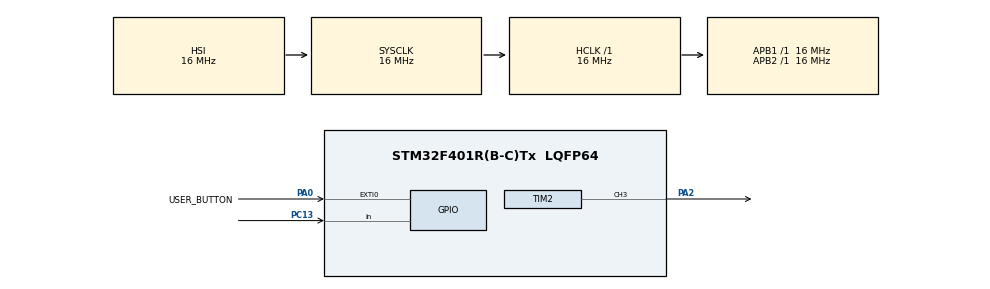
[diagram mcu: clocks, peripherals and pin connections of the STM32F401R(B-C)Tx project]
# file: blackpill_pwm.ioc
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Mcu.Family=STM32F4
Mcu.Name=STM32F401R(B-C)Tx
Mcu.Package=LQFP64
NVIC.EXTI0_IRQn=true\:0\:0\:false\:false\:true\:true\:true\:true
NVIC.PriorityGroup=NVIC_PRIORITYGROUP_4
PA0-WKUP.GPIO_Label=USER_BUTTON
PA0-WKUP.GPIO_ModeDefaultEXTI=GPIO_MODE_IT_FALLING
PA0-WKUP.GPIO_PuPd=GPIO_PULLUP
PA0-WKUP.Signal=GPXTI0
PA2.Signal=S_TIM2_CH3
PC13-ANTI_TAMP.Signal=GPIO_Input
ProjectManager.HeapSize=0x200
ProjectManager.StackSize=0x400
ProjectManager.TargetToolchain=STM32CubeIDE
RCC.AHBFreq_Value=16000000
RCC.APB1Freq_Value=16000000
RCC.APB2Freq_Value=16000000
RCC.CortexFreq_Value=16000000
RCC.HSE_VALUE=25000000
RCC.HSI_VALUE=16000000
RCC.LSE_VALUE=32768
RCC.SYSCLKFreq_VALUE=16000000
RCC.VCOOutputFreq_Value=192000000
SH.S_TIM2_CH3.0=TIM2_CH3,PWM Generation3 CH3
TIM2.Channel-PWM\ Generation3\ CH3=TIM_CHANNEL_3
TIM2.OCPolarity_3=TIM_OCPOLARITY_LOW
TIM2.Period=511
VP_TIM2_VS_ClockSourceINT.Mode=Internal
board=custom

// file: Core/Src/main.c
/* USER CODE BEGIN Header */
/**
  ******************************************************************************
  * @file           : main.c
  * @brief          : Main program body
  ******************************************************************************
  * @attention
  *
  * Copyright (c) 2025 STMicroelectronics.
  * All rights reserved.
  *
  * This software is licensed under terms that can be found in the LICENSE file
  * in the root directory of this software component.
  * If no LICENSE file comes with this software, it is provided AS-IS.
  *
  ******************************************************************************
  */
/* USER CODE END Header */
#include "main.h"

TIM_HandleTypeDef htim2;

void SystemClock_Config(void);
static void MX_GPIO_Init(void);
static void MX_TIM2_Init(void);

/* USER CODE BEGIN 0 */

uint8_t keyPress = 0; //A variable to keep track of no.of times the user button is pressed, set to 0 on startup
uint16_t pwmValue; //A variable to give as input to SET_COMPARE command

void HAL_GPIO_EXTI_Callback(uint16_t GPIO_Pin) //Called whenever user button is pressed
{
	keyPress++; //Increment the variable to denote that the button has been pressed
	if(keyPress>1) //Check if button is pressed has been pressed more than once
	{
		keyPress = 0; //If so reset it back to the "default" state
	}
}

/* USER CODE END 0 */

int main(void)
{

  /* MCU Configuration--------------------------------------------------------*/

  /* Reset of all peripherals, Initializes the Flash interface and the Systick. */
  HAL_Init();

  /* Configure the system clock */
  SystemClock_Config();

  /* Initialize all configured peripherals */
  MX_GPIO_Init();
  MX_TIM2_Init();

  /* Infinite loop */
  while (1)
  {

    /* USER CODE BEGIN 3 */

	  //PWM pin A2 is physically mapped to C13 for making user LED to glow using PWM
	  //Since C13 is an active low pin, PWM's CH polarity is set to low inside ioc file
	  //Otherwise LED will start at max brightness and decrease to min brightness which I don't want

	  if(keyPress) //Only execute if the button is pressed in odd number of times i.e 1st, 3rd, 5th etc as 0th, 2nd, 4th means PWM is OFF
	  {
		 HAL_TIM_PWM_Start(&htim2, TIM_CHANNEL_3); //Start PWM
		 __HAL_TIM_SET_COMPARE(&htim2, TIM_CHANNEL_3, pwmValue); //Set PWM's pulse value on the fly
		 HAL_Delay(3); //Give a short delay between each pulse value to make the brightness change visible
		 if(pwmValue>=512) //Max value of pulse should be less than 512 (counter period is set to 511 aka 9 bits)
		 {
			 pwmValue = 0; //Reset pulse value back to 0
		 }
		 else
		 {
			 pwmValue++; //Increase pulse value by 1
		 }
	  }
	  else //Only execute if the button is pressed in even number of times i.e 2nd, 4th, 6th etc as 1st, 3rd, 5th means PWM is ON
	  {
		  HAL_TIM_PWM_Stop(&htim2, TIM_CHANNEL_3); //Stop PWM to turn OFF the LED
		  pwmValue = 0; //Set pulse value to 0 so that when user presses button to turn PWM back ON, LED will start from min brightness and gradually increase
	  }
  }
  /* USER CODE END 3 */
}

void SystemClock_Config(void)
{
  RCC_OscInitTypeDef RCC_OscInitStruct = {0};
  RCC_ClkInitTypeDef RCC_ClkInitStruct = {0};

  /** Configure the main internal regulator output voltage
  */
  __HAL_RCC_PWR_CLK_ENABLE();
  __HAL_PWR_VOLTAGESCALING_CONFIG(PWR_REGULATOR_VOLTAGE_SCALE2);

  /** Initializes the RCC Oscillators according to the specified parameters
  * in the RCC_OscInitTypeDef structure.
  */
  RCC_OscInitStruct.OscillatorType = RCC_OSCILLATORTYPE_HSI;
  RCC_OscInitStruct.HSIState = RCC_HSI_ON;
  RCC_OscInitStruct.HSICalibrationValue = RCC_HSICALIBRATION_DEFAULT;
  RCC_OscInitStruct.PLL.PLLState = RCC_PLL_NONE;
  if (HAL_RCC_OscConfig(&RCC_OscInitStruct) != HAL_OK)
  {
    Error_Handler();
  }

  /** Initializes the CPU, AHB and APB buses clocks
  */
  RCC_ClkInitStruct.ClockType = RCC_CLOCKTYPE_HCLK|RCC_CLOCKTYPE_SYSCLK
                              |RCC_CLOCKTYPE_PCLK1|RCC_CLOCKTYPE_PCLK2;
  RCC_ClkInitStruct.SYSCLKSource = RCC_SYSCLKSOURCE_HSI;
  RCC_ClkInitStruct.AHBCLKDivider = RCC_SYSCLK_DIV1;
  RCC_ClkInitStruct.APB1CLKDivider = RCC_HCLK_DIV1;
  RCC_ClkInitStruct.APB2CLKDivider = RCC_HCLK_DIV1;

  if (HAL_RCC_ClockConfig(&RCC_ClkInitStruct, FLASH_LATENCY_0) != HAL_OK)
  {
    Error_Handler();
  }
}

static void MX_TIM2_Init(void)
{

  TIM_ClockConfigTypeDef sClockSourceConfig = {0};
  TIM_MasterConfigTypeDef sMasterConfig = {0};
  TIM_OC_InitTypeDef sConfigOC = {0};

  htim2.Instance = TIM2;
  htim2.Init.Prescaler = 0;
  htim2.Init.CounterMode = TIM_COUNTERMODE_UP;
  htim2.Init.Period = 511;
  htim2.Init.ClockDivision = TIM_CLOCKDIVISION_DIV1;
  htim2.Init.AutoReloadPreload = TIM_AUTORELOAD_PRELOAD_DISABLE;
  if (HAL_TIM_Base_Init(&htim2) != HAL_OK)
  {
    Error_Handler();
  }
  sClockSourceConfig.ClockSource = TIM_CLOCKSOURCE_INTERNAL;
  if (HAL_TIM_ConfigClockSource(&htim2, &sClockSourceConfig) != HAL_OK)
  {
    Error_Handler();
  }
  if (HAL_TIM_PWM_Init(&htim2) != HAL_OK)
  {
    Error_Handler();
  }
  sMasterConfig.MasterOutputTrigger = TIM_TRGO_RESET;
  sMasterConfig.MasterSlaveMode = TIM_MASTERSLAVEMODE_DISABLE;
  if (HAL_TIMEx_MasterConfigSynchronization(&htim2, &sMasterConfig) != HAL_OK)
  {
    Error_Handler();
  }
  sConfigOC.OCMode = TIM_OCMODE_PWM1;
  sConfigOC.Pulse = 0;
  sConfigOC.OCPolarity = TIM_OCPOLARITY_LOW;
  sConfigOC.OCFastMode = TIM_OCFAST_DISABLE;
  if (HAL_TIM_PWM_ConfigChannel(&htim2, &sConfigOC, TIM_CHANNEL_3) != HAL_OK)
  {
    Error_Handler();
  }
  HAL_TIM_MspPostInit(&htim2);

}

static void MX_GPIO_Init(void)
{
  GPIO_InitTypeDef GPIO_InitStruct = {0};

  /* GPIO Ports Clock Enable */
  __HAL_RCC_GPIOC_CLK_ENABLE();
  __HAL_RCC_GPIOA_CLK_ENABLE();

  /*Configure GPIO pin : PC13 */
  GPIO_InitStruct.Pin = GPIO_PIN_13;
  GPIO_InitStruct.Mode = GPIO_MODE_INPUT;
  GPIO_InitStruct.Pull = GPIO_NOPULL;
  HAL_GPIO_Init(GPIOC, &GPIO_InitStruct);

  /*Configure GPIO pin : USER_BUTTON_Pin */
  GPIO_InitStruct.Pin = USER_BUTTON_Pin;
  GPIO_InitStruct.Mode = GPIO_MODE_IT_FALLING;
  GPIO_InitStruct.Pull = GPIO_PULLUP;
  HAL_GPIO_Init(USER_BUTTON_GPIO_Port, &GPIO_InitStruct);

  /* EXTI interrupt init*/
  HAL_NVIC_SetPriority(EXTI0_IRQn, 0, 0);
  HAL_NVIC_EnableIRQ(EXTI0_IRQn);

}

void Error_Handler(void)
{
  __disable_irq();
  while (1)
  {
  }
}
